# CH32V20xxx register map
Vendor: WCH Ltd.; File version: 1.0
Registers are 32-bit, read-write, reset 0x0 unless marked. A register's access mark holds for its fields unless they carry their own. Offsets are from the block's base; [hi:lo] are bit positions.

## SPI1 — Serial peripheral interface
Base 0x40013000
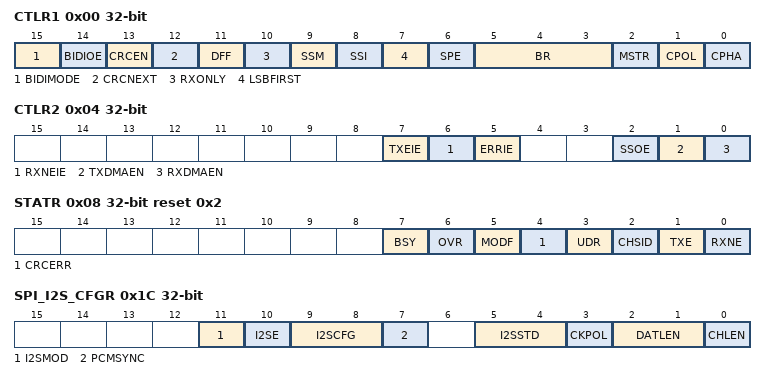
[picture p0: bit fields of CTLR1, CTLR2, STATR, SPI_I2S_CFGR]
0x00 CTLR1 — control register 1
  [15] BIDIMODE — Bidirectional data mode enable
  [14] BIDIOE — Output enable in bidirectional mode
  [13] CRCEN — Hardware CRC calculation enable
  [12] CRCNEXT — CRC transfer next
  [11] DFF — Data frame format
  [10] RXONLY — Receive only
  [9] SSM — Software slave management
  [8] SSI — Internal slave select
  [7] LSBFIRST — Frame format
  [6] SPE — SPI enable
  [5:3] BR — Baud rate control
  [2] MSTR — Master selection
  [1] CPOL — Clock polarity
  [0] CPHA — Clock phase
0x04 CTLR2 — control register 2
  [7] TXEIE — Tx buffer empty interrupt enable
  [6] RXNEIE — RX buffer not empty interrupt enable
  [5] ERRIE — Error interrupt enable
  [2] SSOE — SS output enable
  [1] TXDMAEN — Tx buffer DMA enable
  [0] RXDMAEN — Rx buffer DMA enable
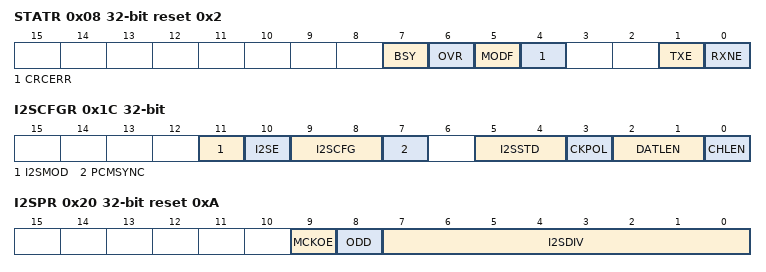
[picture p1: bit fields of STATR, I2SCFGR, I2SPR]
0x08 STATR access per field reset 0x2 — status register
  [7] BSY ro — Busy flag
  [6] OVR rw — Overrun flag
  [5] MODF ro — Mode fault
  [4] CRCERR rw — CRC error flag
  [3] UDR ro — Underrun flag
  [2] CHSID ro — Channel side
  [1] TXE ro — Transmit buffer empty
  [0] RXNE ro — Receive buffer not empty
0x0C DATAR — data register
  [15:0] DATAR — Data register
0x10 CRCR reset 0x7 — CRCR polynomial register
  [15:0] CRCPOLY — CRC polynomial register
0x14 RCRCR ro — RX CRC register
  [15:0] RXCRC
0x18 TCRCR ro — send CRC register
  [15:0] TXCRC
0x1C SPI_I2S_CFGR — SPI_I2S configure register
  [11] I2SMOD — I2S mode selection
  [10] I2SE — I2S Enable
  [9:8] I2SCFG — I2SCFG[1:0] bits (I2S configuration mode)
  [7] PCMSYNC — PCM frame synchronization
  [5:4] I2SSTD — I2SSTD[1:0] bits (I2S standard selection)
  [3] CKPOL — steady state clock polarity
  [2:1] DATLEN — DATLEN[1:0] bits (Data length to be transferred)
  [0] CHLEN — Channel length (number of bits per audio channel)
0x24 HSCR — high speed control register
  [0] HSRXEN — High speed mode read enable

## SPI2 — Serial peripheral interface
Base 0x40003800
Same registers: SPI3 0x40003C00
Registers as SPI1, without SPI_I2S_CFGR; these are added or differ:
0x08 STATR access per field reset 0x2 — status register
  [7] BSY ro — Busy flag
  [6] OVR ro — Overrun flag
  [5] MODF ro — Mode fault
  [4] CRCERR rw — CRC error flag
  [1] TXE ro — Transmit buffer empty
  [0] RXNE ro — Receive buffer not empty
0x18 TCRCR ro — TX CRC register
  [15:0] TXCRC
0x1C I2SCFGR — I2S configuration register
  [11] I2SMOD — I2S mode selection
  [10] I2SE — I2S Enable
  [9:8] I2SCFG — I2S configuration mode
  [7] PCMSYNC — PCM frame synchronization
  [5:4] I2SSTD — I2S standard selection
  [3] CKPOL — Steady state clock polarity
  [2:1] DATLEN — Data length to be transferred
  [0] CHLEN — Channel length (number of bits per audio channel)
0x20 I2SPR reset 0xA — I2S prescaler register
  [9] MCKOE — Master clock output enable
  [8] ODD — Odd factor for the prescaler
  [7:0] I2SDIV — I2S Linear prescaler

## USART1 — Universal synchronous asynchronous receiver transmitter
Base 0x40013800
Same registers: UART6 0x40001800, UART7 0x40001C00, UART8 0x40002000, USART2 0x40004400, USART3 0x40004800, UART4 0x40004C00, UART5 0x40005000
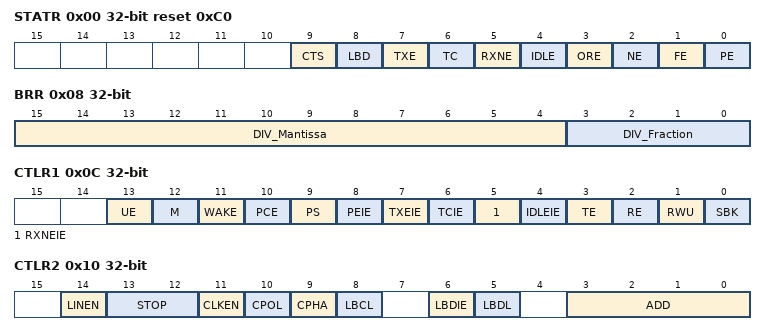
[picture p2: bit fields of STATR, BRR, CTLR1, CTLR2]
0x00 STATR access per field reset 0xC0 — Status register
  [9] CTS rw — CTS flag
  [8] LBD rw — LIN break detection flag
  [7] TXE ro — Transmit data register empty
  [6] TC rw — Transmission complete
  [5] RXNE rw — Read data register not empty
  [4] IDLE ro — IDLE line detected
  [3] ORE ro — Overrun error
  [2] NE ro — Noise error flag
  [1] FE ro — Framing error
  [0] PE ro — Parity error
0x04 DATAR — Data register
  [8:0] DR — Data value
0x08 BRR — Baud rate register
  [15:4] DIV_Mantissa — mantissa of USARTDIV
  [3:0] DIV_Fraction — fraction of USARTDIV
0x0C CTLR1 — Control register 1
  [13] UE — USART enable
  [12] M — Word length
  [11] WAKE — Wakeup method
  [10] PCE — Parity control enable
  [9] PS — Parity selection
  [8] PEIE — PE interrupt enable
  [7] TXEIE — TXE interrupt enable
  [6] TCIE — Transmission complete interrupt enable
  [5] RXNEIE — RXNE interrupt enable
  [4] IDLEIE — IDLE interrupt enable
  [3] TE — Transmitter enable
  [2] RE — Receiver enable
  [1] RWU — Receiver wakeup
  [0] SBK — Send break
0x10 CTLR2 — Control register 2
  [14] LINEN — LIN mode enable
  [13:12] STOP — STOP bits
  [11] CLKEN — Clock enable
  [10] CPOL — Clock polarity
  [9] CPHA — Clock phase
  [8] LBCL — Last bit clock pulse
  [6] LBDIE — LIN break detection interrupt enable
  [5] LBDL — lin break detection length
  [3:0] ADD — Address of the USART node
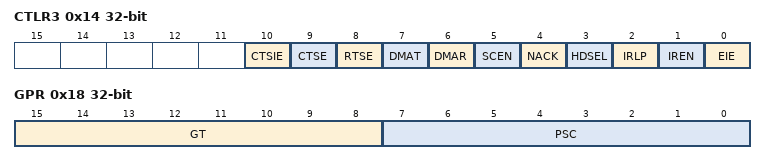
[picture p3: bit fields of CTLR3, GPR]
0x14 CTLR3 — Control register 3
  [10] CTSIE — CTS interrupt enable
  [9] CTSE — CTS enable
  [8] RTSE — RTS enable
  [7] DMAT — DMA enable transmitter
  [6] DMAR — DMA enable receiver
  [5] SCEN — Smartcard mode enable
  [4] NACK — Smartcard NACK enable
  [3] HDSEL — Half-duplex selection
  [2] IRLP — IrDA low-power
  [1] IREN — IrDA mode enable
  [0] EIE — Error interrupt enable
0x18 GPR — Guard time and prescaler register
  [15:8] GT — Guard time value
  [7:0] PSC — Prescaler value
